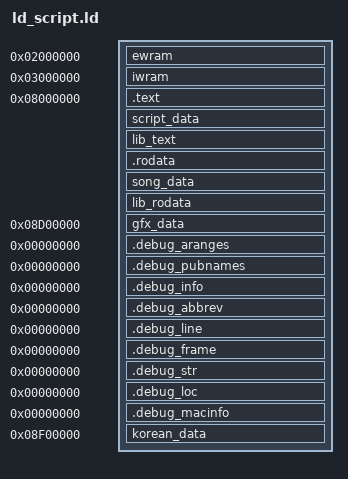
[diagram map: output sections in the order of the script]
ENTRY(Start)

gNumMusicPlayers = 4;
gMaxLines = 60;

SECTIONS {
    . = 0x2000000;

    ewram (NOLOAD) :
    ALIGN(4)
    {
. = ALIGN(4);
src/engine/main.o(ewram_data);
. = ALIGN(4);
src/engine/sprite.o(ewram_data);
. = ALIGN(4);
src/engine/text.o(ewram_data);
. = ALIGN(4);
src/engine/string_util.o(ewram_data);
. += 0x2E8;
. = ALIGN(4);
src/engine/link.o(ewram_data);
. = ALIGN(4);
src/rom3.o(ewram_data);
. = ALIGN(4);
gUnknown_020238C8 = .;
. += 0x4;
gDisplayedStringBattle = .;
. += 0x12C;
gBattleTypeFlags = .;
. += 0x4;
gUnknown_020239FC = .;
. += 0x4;
gUnknown_02023A00 = .;
. += 0x4;
gUnknown_02023A04 = .;
. += 0x10;
gUnknown_02023A14 = .;
. += 0x4C;
gBattleBufferA = .;
. += 0x2;
gUnknown_02023A62 = .;
. += 0x1;
gUnknown_02023A63 = .;
. += 0x1;
gUnknown_02023A64 = .;
. += 0x7FC;
gBattleBufferB = .;
. += 0x4;
gUnknown_02024264 = .;
. += 0x7FC;
gActiveBank = .;
. += 0x4;
gBattleExecBuffer = .;
. += 0x4;
gNoOfAllBanks = .;
. += 0x2;
gBattlePartyID = .;
. += 0x8;
gBanksBySide = .;
. += 0x4;
gUnknown_02024A76 = .;
. += 0x4;
gTurnOrder = .;
. += 0x4;
gCurrentMoveTurn = .;
. += 0x1;
gFightStateTracker = .;
. += 0x1;
gBattleMons = .;
. += 0xC;
gUnknown_02024A8C = .;
. += 0xC;
gUnknown_02024A98 = .;
. += 0xC;
gUnknown_02024AA4 = .;
. += 0x4;
gUnknown_02024AA8 = .;
. += 0x24;
gUnknown_02024ACC = .;
. += 0x4;
gUnknown_02024AD0 = .;
. += 0x110;
gObjectBankIDs = .;
. += 0x4;
gCurrMovePos = .;
. += 0x1;
gUnknown_02024BE5 = .;
. += 0x1;
gCurrentMove = .;
. += 0x2;
gUnknown_02024BE8 = .;
. += 0x2;
gRandomMove = .;
. += 0x2;
gBattleMoveDamage = .;
. += 0x4;
gHP_dealt = .;
. += 0x4;
gTakenDmg = .;
. += 0x10;
gLastUsedItem = .;
. += 0x2;
gLastUsedAbility = .;
. += 0x1;
gBankAttacker = .;
. += 0x1;
gBankTarget = .;
. += 0x1;
gBank1 = .;
. += 0x1;
gEffectBank = .;
. += 0x1;
gStringBank = .;
. += 0x1;
gAbsentBankFlags = .;
. += 0x1;
gCritMultiplier = .;
. += 0x1;
gMultiHitCounter = .;
. += 0x2;
gBattlescriptCurrInstr = .;
. += 0x8;
gActionForBanks = .;
. += 0x4;
gUnknown_02024C1C = .;
. += 0x10;
gUnknown_02024C2C = .;
. += 0x8;
gLastUsedMove = .;
. += 0x8;
gMoveHitWith = .;
. += 0x8;
gUnknown_02024C44 = .;
. += 0x8;
gUnknown_02024C4C = .;
. += 0x8;
gLockedMove = .;
. += 0x8;
gUnknown_02024C5C = .;
. += 0x4;
gChosenMovesByBanks = .;
. += 0x8;
gBattleMoveFlags = .;
. += 0x4;
gHitMarker = .;
. += 0x4;
gUnknown_02024C70 = .;
. += 0x4;
gTakenDmgBanks = .;
. += 0x4;
gUnknown_02024C78 = .;
. += 0x2;
gSideAffecting = .;
. += 0x6;
gSideTimer = .;
. += 0x18;
gStatuses3 = .;
. += 0x10;
gDisableStructs = .;
. += 0x70;
gPauseCounterBattle = .;
. += 0x2;
gPaydayMoney = .;
. += 0x2;
gRandomTurnNumber = .;
. += 0x2;
gBattleCommunication = .;
. += 0x1;
gUnknown_02024D1F = .;
. += 0x7;
gBattleOutcome = .;
. += 0x2;
gProtectStructs = .;
. += 0x40;
gSpecialStatuses = .;
. += 0x50;
gBattleWeather = .;
. += 0x4;
gWishFutureKnock = .;
. += 0x20;
gUnknown_02024DDC = .;
. += 0xC;
gUnknown_02024DE8 = .;
. += 0x2;
gSentPokesToOpponent = .;
. += 0x2;
gDynamicBasePower = .;
. += 0x2;
gExpShareExp = .;
. += 0x2;
gEnigmaBerries = .;
. += 0x8;
gUnknown_02024DF8 = .;
. += 0x68;
gActionSelectionCursor = .;
. += 0x4;
gMoveSelectionCursor = .;
. += 0x4;
gUnknown_02024E68 = .;
. += 0x4;
gBankInMenu = .;
. += 0x1;
gDoingBattleAnim = .;
. += 0x3;
gPID_perBank = .;
. += 0x10;
gBattleMovePower = .;
. += 0x2;
gMoveToLearn = .;
. += 0x2;
gBattleMonForms = .;
. += 0x4;
. = ALIGN(4);
src/pokemon/pokemon_1.o(ewram_data);
. = ALIGN(4);
src/pokemon/pokemon_2.o(ewram_data);
. = ALIGN(4);
src/engine/load_save.o(ewram_data);
gUnknown_020296CC = .;
. += 0x34;
gUnknown_02029700 = .;
. += 0xD8;
gUnknown_020297D8 = .;
. += 0x4;
. = ALIGN(4);
src/scene/berry_blender.o(ewram_data);
. = ALIGN(4);
src/scene/new_game.o(ewram_data);
. = ALIGN(4);
src/field/overworld.o(ewram_data);
. = ALIGN(4);
src/field/fieldmap.o(ewram_data);
. = ALIGN(4);
src/field/field_camera.o(ewram_data);
. = ALIGN(4);
src/field/field_player_avatar.o(ewram_data);
. = ALIGN(4);
src/field/field_message_box.o(ewram_data);
. = ALIGN(4);
src/engine/script.o(ewram_data);
. = ALIGN(4);
src/field/scrcmd.o(ewram_data);
. = ALIGN(4);
src/field/field_control_avatar.o(ewram_data);
. = ALIGN(4);
src/field/event_data.o(ewram_data);
. = ALIGN(4);
gUnknown_0202E8F4 = .;
. += 0x1;
gUnknown_0202E8F5 = .;
. += 0x1;
gUnknown_0202E8F6 = .;
. += 0x2;
gUnknown_0202E8F8 = .;
. += 0x2;
gPartyMenuType = .;
. += 0x2;
. = ALIGN(4);
src/field/start_menu.o(ewram_data);
. = ALIGN(4);
src/engine/menu.o(ewram_data);
. = ALIGN(4);
src/engine/tileset_anim.o(ewram_data);
. = ALIGN(4);
src/engine/palette.o(ewram_data);
. = ALIGN(4);
src/engine/sound.o(ewram_data);
. = ALIGN(4);
src/battle/battle_anim.o(ewram_data);
. = ALIGN(4);
src/rom_8077ABC.o(ewram_data);
. = ALIGN(4);
src/scene/title_screen.o(ewram_data);
. = ALIGN(4);
gUnknown_0202F7E8 = .;
. += 0x200;
gUnknown_0202F9E8 = .;
. += 0x260;
gUnknown_0202FC48 = .;
. += 0x2F0;
gUnknown_0202FF38 = .;
. += 0x20;
gUnknown_0202FF58 = .;
. += 0x4;
. = ALIGN(4);
src/battle/battle_setup.o(ewram_data);
. = ALIGN(4);
src/field/wild_encounter.o(ewram_data);
. = ALIGN(4);
src/field/field_effect.o(ewram_data);
gUnknown_0202FFA4 = .;
. += 0x4;
. = ALIGN(4);
src/pokemon/pokemon_menu.o(ewram_data);
. = ALIGN(4);
src/pokemon/pokedex.o(ewram_data);
. = ALIGN(4);
src/engine/trainer_card.o(ewram_data);
. = ALIGN(4);
src/pokemon/pokemon_storage_system.o(ewram_data);
. = ALIGN(4);
gUnknown_02038470 = .;
. += 0x3;
gUnknown_02038473 = .;
. += 0x1;
gUnknown_02038474 = .;
. += 0x4;
gUnknown_02038478 = .;
. += 0x4;
gUnknown_0203847C = .;
. += 0x1;
gUnknown_0203847D = .;
. += 0x1;
gUnknown_0203847E = .;
. += 0x1;
gUnknown_0203847F = .;
. += 0x1;
gUnknown_02038480 = .;
. += 0x64;
gUnknown_020384E4 = .;
. += 0x1;
gUnknown_020384E5 = .;
. += 0x1;
gUnknown_020384E6 = .;
. += 0x1;
gUnknown_020384E7 = .;
. += 0x1;
gUnknown_020384E8 = .;
. += 0x1;
gUnknown_020384E9 = .;
. += 0x1;
gUnknown_020384EA = .;
. += 0x2;
gUnknown_020384EC = .;
. += 0x4;
gUnknown_020384F0 = .;
. += 0x4;
gUnknown_020384F4 = .;
. += 0x4;
. = ALIGN(4);
src/field/script_movement.o(ewram_data);
. = ALIGN(4);
src/field/map_name_popup.o(ewram_data);
. = ALIGN(4);
src/field/item_menu.o(ewram_data);
. = ALIGN(4);
gUnknown_0203856C = .;
. += 0x4;
gContestMons = .;
. += 0xD;
gUnknown_0203857D = .;
. += 0x11;
gUnknown_0203858E = .;
. += 0x8;
gUnknown_02038596 = .;
. += 0xDA;
gUnknown_02038670 = .;
. += 0x8;
gUnknown_02038678 = .;
. += 0x8;
gUnknown_02038680 = .;
. += 0x8;
gUnknown_02038688 = .;
. += 0x8;
gUnknown_02038690 = .;
. += 0x4;
gUnknown_02038694 = .;
. += 0x1;
gContestPlayerMonIndex = .;
. += 0x1;
gUnknown_02038696 = .;
. += 0x4;
gIsLinkContest = .;
. += 0x1;
gUnknown_0203869B = .;
. += 0x1;
gScriptContestCategory = .;
. += 0x2;
gScriptContestRank = .;
. += 0x2;
. = ALIGN(4);
src/field/shop.o(ewram_data);
. = ALIGN(4);
src/field/money.o(ewram_data);
. = ALIGN(4);
gUnknown_02038738 = .;
. += 0x78;
. = ALIGN(4);
src/debug/sound_check_menu.o(ewram_data);
. = ALIGN(4);
gUnknown_020387DC = .;
. += 0x4;
. = ALIGN(4);
src/field/tv.o(ewram_data);
. = ALIGN(4);
gUnknown_020387EC = .;
. += 0x4;
. = ALIGN(4);
src/field/rotating_gate.o(ewram_data);
. = ALIGN(4);
src/field/safari_zone.o(ewram_data);
gUnknown_020388AC = .;
. += 0x4;
gUnknown_020388B0 = .;
. += 0x4;
gUnknown_020388B4 = .;
. += 0x4;
. = ALIGN(4);
src/pokemon/mon_markings.o(ewram_data);
. = ALIGN(4);
src/field/mauville_man.o(ewram_data);
. = ALIGN(4);
src/field/menu_helpers.o(ewram_data);
. = ALIGN(4);
src/field/region_map.o(ewram_data);
. = ALIGN(4);
src/field/decoration.o(ewram_data);
. = ALIGN(4);
src/battle/battle_ai.o(ewram_data);
. = ALIGN(4);
src/rom6.o(ewram_data);
. = ALIGN(4);
src/field/pokeblock.o(ewram_data);
. = ALIGN(4);
src/field/field_specials.o(ewram_data);
. = ALIGN(4);
gUnknown_02039260 = .;
. += 0x2;
gUnknown_02039262 = .;
. += 0x2;
gUnknown_02039264 = .;
. += 0x2;
gUnknown_02039266 = .;
. += 0x2;
gUnknown_02039268 = .;
. += 0x2;
gUnknown_0203926A = .;
. += 0x2;
gAbilitiesPerBank = .;
. += 0x4;
. = ALIGN(4);
src/field/choose_party.o(ewram_data);
. = ALIGN(4);
gUnknown_02039274 = .;
. += 0x4;
gUnknown_02039278 = .;
. += 0x1;
gUnknown_02039279 = .;
. += 0x1;
gUnknown_0203927A = .;
. += 0x1;
gUnknown_0203927B = .;
. += 0x1;
gUnknown_0203927C = .;
. += 0x1;
gUnknown_0203927D = .;
. += 0x7;
. = ALIGN(4);
src/engine/save.o(ewram_data);
. = ALIGN(4);
src/engine/mystery_event_script.o(ewram_data);
. = ALIGN(4);
src/field/roamer.o(ewram_data);
. = ALIGN(4);
src/field/use_pokeblock.o(ewram_data);
. = ALIGN(4);
src/field/player_pc.o(ewram_data);
. = ALIGN(4);
src/scene/intro.o(ewram_data);
. = ALIGN(4);
src/scene/hall_of_fame.o(ewram_data);
. = ALIGN(4);
src/scene/credits.o(ewram_data);
. = ALIGN(4);
src/field/lottery_corner.o(ewram_data);
. = ALIGN(4);
src/field/berry_tag_screen.o(ewram_data);
. = ALIGN(4);
src/engine/mystery_event_menu.o(ewram_data);
. = ALIGN(4);
src/engine/save_failed_screen.o(ewram_data);
. = ALIGN(4);
src/pokemon/pokeblock_feed.o(ewram_data);
gUnknown_02039358 = .;
. += 0x2;
gUnknown_0203935A = .;
. += 0x2;
gUnknown_0203935C = .;
. += 0x4;
gTileBuffer = .;
. += 0x100;
gUnknown_02039460 = .;
. += 0x300;
gUnknown_02039760 = .;
. += 0xC00;
gUnknown_0203A360 = .;
. += 0x20;
. = ALIGN(4);
src/engine/menu_cursor.o(ewram_data);

        . = 0x40000;
    }

    . = 0x3000000;

    iwram (NOLOAD) :
    ALIGN(4)
    {
        /* .bss starts at 0x3000000 */
. = ALIGN(4);
src/engine/main.o(.bss);
. = ALIGN(4);
src/engine/sprite.o(.bss);
. = ALIGN(4);
src/engine/text.o(.bss);
. = ALIGN(4);
src/engine/string_util.o(.bss);
. = ALIGN(4);
src/engine/link.o(.bss);
. = ALIGN(4);
src/engine/rtc.o(.bss);
. = ALIGN(4);
src/field/daycare.o(.bss);
. = ALIGN(4);
src/engine/trade.o(.bss);
. = ALIGN(4);
src/scene/berry_blender.o(.bss);
. = ALIGN(4);
src/engine/play_time.o(.bss);
. = ALIGN(4);
src/field/overworld.o(.bss);
. = ALIGN(4);
src/field/field_camera.o(.bss);
. = ALIGN(4);
src/field/field_map_obj.o(.bss);
. = ALIGN(4);
src/field/field_message_box.o(.bss);
. = ALIGN(4);
src/engine/text_window.o(.bss);
. = ALIGN(4);
src/engine/script.o(.bss);
. = ALIGN(4);
src/field/start_menu.o(.bss);
. = ALIGN(4);
src/engine/menu.o(.bss);
. = ALIGN(4);
src/engine/tileset_anim.o(.bss);
. = ALIGN(4);
src/engine/sound.o(.bss);
. = ALIGN(4);
src/field/field_weather.o(.bss);
. = ALIGN(4);
src/field/field_effect.o(.bss);
. = ALIGN(4);
src/field/item_menu.o(.bss);
. = ALIGN(4);
src/field/shop.o(.bss);
. = ALIGN(4);
src/engine/record_mixing.o(.bss);
. = ALIGN(4);
src/field/tv.o(.bss);
. = ALIGN(4);
src/battle/battle_anim_80CA710.o(.bss);
. = ALIGN(4);
src/field/easy_chat.o(.bss);
. = ALIGN(4);
src/pokenav_before.o(.bss);
. = ALIGN(4);
src/field/mauville_man.o(.bss);
. = ALIGN(4);
src/field/menu_helpers.o(.bss);
. = ALIGN(4);
src/scene/contest_painting.o(.bss);
. = ALIGN(4);
src/field/pokeblock.o(.bss);
. = ALIGN(4);
src/field/field_specials.o(.bss);
. = ALIGN(4);
src/pokemon/learn_move.o(.bss);
. = ALIGN(4);
src/field/player_pc.o(.bss);
. = ALIGN(4);
asm/m4a_1.o(.bss);
. = ALIGN(4);
src/libs/agb_flash.o(.bss);
. = ALIGN(4);
src/libs/siirtc.o(.bss);
. = ALIGN(4);
../../tools/agbcc/lib/libgcc.a:dp-bit.o(.bss);
. = ALIGN(4);
../../tools/agbcc/lib/libgcc.a:fp-bit.o(.bss);

        /* .bss.code starts at 0x3000F60 */
        src/libs/m4a_2.o(.bss.code);

        /* COMMON starts at 0x3001760 */
. = ALIGN(4);
. = ALIGN(4);
gKeyRepeatStartDelay = .;
. += 0x4;
. = ALIGN(4);
gLinkTransferringData = .;
. += 0x4;
. = ALIGN(16);
gMain = .;
. += 0x440;
. = ALIGN(4);
gKeyRepeatContinueDelay = .;
. += 0x4;
. = ALIGN(4);
gSoftResetDisabled = .;
. += 0x4;
. = ALIGN(16);
gIntrTable = .;
. += 0x38;
. = ALIGN(4);
gLinkVSyncDisabled = .;
. += 0x4;
. = ALIGN(16);
IntrMain_Buffer = .;
. += 0x800;
. = ALIGN(4);
gPcmDmaCounter = .;
. += 0x4;
. = ALIGN(4);
. = ALIGN(16);
gSpriteOrder = .;
. += 0x40;
. = ALIGN(16);
gSpriteTileAllocBitmap = .;
. += 0x80;
. = ALIGN(4);
gSpriteCoordOffsetX = .;
. += 0x4;
. = ALIGN(4);
gOamLimit = .;
. += 0x4;
. = ALIGN(4);
gReservedSpriteTileCount = .;
. += 0x4;
. = ALIGN(4);
gSpriteCopyRequestCount = .;
. += 0x4;
. = ALIGN(16);
gSpriteCopyRequests = .;
. += 0x300;
. = ALIGN(4);
gSpriteCoordOffsetY = .;
. += 0x4;
. = ALIGN(16);
gOamMatrices = .;
. += 0x100;
. = ALIGN(4);
gShouldProcessSpriteCopyRequests = .;
. += 0x4;
. = ALIGN(4);
gOamMatrixAllocBitmap = .;
. += 0x4;
. = ALIGN(4);
gReservedSpritePaletteCount = .;
. += 0x4;
. = ALIGN(4);
. = ALIGN(16);
gUnknownStringVar = .;
. += 0x10;
. = ALIGN(4);
. = ALIGN(8);
word_3002910 = .;
. += 0x8;
. = ALIGN(4);
gLinkDebugValue1 = .;
. += 0x4;
. = ALIGN(16);
localLinkPlayerBlock = .;
. += 0x3C;
. = ALIGN(4);
gLinkErrorOccurred = .;
. += 0x4;
. += 0x4;
. = ALIGN(4);
gLinkDebugValue2 = .;
. += 0x4;
. += 0x4;
. = ALIGN(4);
gLinkPlayerPending = .;
. += 0x4;
. = ALIGN(16);
gLinkPlayers = .;
. += 0x70;
. = ALIGN(4);
gBlockReceived = .;
. += 0x4;
. += 0x4;
. = ALIGN(4);
gLinkHeldKeys = .;
. += 0x4;
. = ALIGN(4);
gLinkTimeOutCounter = .;
. += 0x4;
. += 0x4;
. = ALIGN(16);
localLinkPlayer = .;
. += 0x1C;
. = ALIGN(16);
gRecvCmds = .;
. += 0x40;
. = ALIGN(4);
gLinkStatus = .;
. += 0x4;
. = ALIGN(4);
gLinkDummyBool = .;
. += 0x4;
. = ALIGN(4);
byte_3002A68 = .;
. += 0x4;
. = ALIGN(16);
gBlockSendBuffer = .;
. += 0x100;
. = ALIGN(4);
u8_array_3002B70 = .;
. += 0x4;
. = ALIGN(4);
gLinkType = .;
. += 0x4;
. = ALIGN(4);
u8_array_3002B78 = .;
. += 0x4;
. = ALIGN(16);
gBlockRecvBuffer = .;
. += 0x400;
. = ALIGN(4);
gSuppressLinkErrorMessage = .;
. += 0x4;
. = ALIGN(4);
gSavedLinkPlayerCount = .;
. += 0x4;
. = ALIGN(16);
gSendCmd = .;
. += 0x10;
. = ALIGN(4);
gSavedMultiplayerId = .;
. += 0x4;
. = ALIGN(4);
gReceivedRemoteLinkPlayers = .;
. += 0x4;
. = ALIGN(16);
gLinkTestBGInfo = .;
. += 0x10;
. = ALIGN(4);
gLinkCallback = .;
. += 0x4;
. = ALIGN(16);
gSavedLinkPlayers = .;
. += 0x70;
. = ALIGN(4);
gShouldAdvanceLinkState = .;
. += 0x4;
. = ALIGN(8);
gLinkTestBlockChecksums = .;
. += 0x8;
. += 0x4;
. = ALIGN(4);
gBlockRequestType = .;
. += 0x4;
. += 0x4;
. += 0x4;
. = ALIGN(4);
gLastSendQueueCount = .;
. += 0x4;
. = ALIGN(16);
gLink = .;
. += 0xFC0;
. = ALIGN(4);
gLastRecvQueueCount = .;
. += 0x4;
. = ALIGN(4);
gLinkSavedIme = .;
. += 0x4;
. = ALIGN(4);
. = ALIGN(8);
gLocalTime = .;
. += 0x8;
. = ALIGN(4);
. = ALIGN(16);
gBattleBuffersTransferData = .;
. += 0x170;
. = ALIGN(4);
gUnknown_030041B0 = .;
. += 0x4;
gUnknown_030041B4 = .;
. += 0x4;
gUnknown_030041B8 = .;
. += 0x8;
gBattleTextBuff1 = .;
. += 0x10;
gUnknown_030041D0 = .;
. += 0x30;
gUnknown_03004200 = .;
. += 0x10;
gUnknown_03004210 = .;
. += 0x30;
gUnknown_03004240 = .;
. += 0x4;
gUnknown_03004244 = .;
. += 0xC;
gUnknown_03004250 = .;
. += 0x30;
gUnknown_03004280 = .;
. += 0x4;
gUnknown_03004284 = .;
. += 0x4;
gUnknown_03004288 = .;
. += 0x4;
gBattleTerrain = .;
. += 0x4;
gBattleTextBuff2 = .;
. += 0x10;
gUnknown_030042A0 = .;
. += 0x4;
gUnknown_030042A4 = .;
. += 0xC;
gBattleTextBuff3 = .;
. += 0x10;
gUnknown_030042C0 = .;
. += 0x4;
gUnknown_030042C4 = .;
. += 0xC;
gPreBattleCallback1 = .;
. += 0x4;
gBattleMainFunc = .;
. += 0xC;
gBattleResults = .;
. += 0x1C;
gUnknown_030042FC = .;
. += 0xE;
gUnknown_0300430A = .;
. += 0xC;
gUnknown_03004316 = .;
. += 0xE;
gLeveledUpInBattle = .;
. += 0xC;
gBattleBankFunc = .;
. += 0x10;
gHealthboxIDs = .;
. += 0x4;
gUnknown_03004344 = .;
. += 0x4;
gUnknown_03004348 = .;
. += 0x4;
gUnknown_0300434C = .;
. += 0x4;
. = ALIGN(4);
. = ALIGN(4);
gPlayerPartyCount = .;
. += 0x4;
. = ALIGN(16);
gPlayerParty = .;
. += 0x258;
. = ALIGN(4);
gEnemyPartyCount = .;
. += 0x4;
. = ALIGN(16);
gEnemyParty = .;
. += 0x258;
. = ALIGN(4);
. = ALIGN(4);
gRngValue = .;
. += 0x4;
. = ALIGN(4);
. = ALIGN(4);
gEggHatchData = .;
. += 0x4;
. = ALIGN(4);
. = ALIGN(4);
gFlashMemoryPresent = .;
. += 0x4;
gUnknown_03004824 = .;
. += 0x4;
gUnknown_03004828 = .;
. += 0x8;
. = ALIGN(4);
. = ALIGN(4);
gUnknown_03004830 = .;
. += 0x4;
. = ALIGN(4);
gInGameOpponentsNo = .;
. += 0x4;
. = ALIGN(16);
gUnknown_03004840 = .;
. += 0x14;
. = ALIGN(4);
gBerryBlenderData = .;
. += 0x4;
. = ALIGN(4);
. = ALIGN(4);
word_3004858 = .;
. += 0x4;
. = ALIGN(4);
gFieldCallback = .;
. += 0x4;
. = ALIGN(4);
gUnknown_03004860 = .;
. += 0x4;
. = ALIGN(4);
gFieldLinkPlayerCount = .;
. += 0x4;
. = ALIGN(4);
. = ALIGN(16);
gUnknown_03004870 = .;
. += 0xC;
. = ALIGN(4);
. = ALIGN(16);
gUnknown_03004880 = .;
. += 0x18;
. = ALIGN(4);
gUnknown_03004898 = .;
. += 0x4;
. = ALIGN(4);
gUnknown_0300489C = .;
. += 0x4;
. = ALIGN(4);
. = ALIGN(16);
gMapObjects = .;
. += 0x240;
. = ALIGN(4);
. = ALIGN(4);
gSelectedMapObject = .;
. += 0x4;
. = ALIGN(4);
gUnknown_03004AE4 = .;
. += 0x4;
. = ALIGN(4);
. = ALIGN(4);
gCallback_03004AE8 = .;
. += 0x4;
. = ALIGN(4);
. = ALIGN(4);
gDisableMusic = .;
. += 0x4;
. = ALIGN(4);
. = ALIGN(4);
gSoundAnimFramesToWait = .;
. += 0x4;
. = ALIGN(16);
gBattleAnimArgs = .;
. += 0x10;
. = ALIGN(16);
gAnimSpriteIndexArray = .;
. += 0x10;
. = ALIGN(4);
. = ALIGN(16);
gTasks = .;
. += 0x280;
. = ALIGN(4);
. = ALIGN(16);
gUnknown_03004DA0 = .;
. += 0x20;
. = ALIGN(16);
gUnknown_03004DC0 = .;
. += 0x20;
gUnknown_03004DE0 = .;
. += 0x2;
gUnknown_03004DE2 = .;
. += 0x2;
gUnknown_03004DE4 = .;
. += 0x27C;
gUnknown_03005060 = .;
. += 0x500;
gUnknown_03005560 = .;
. += 0x140;
gUnknown_030056A0 = .;
. += 0x640;
. = ALIGN(4);
. = ALIGN(4);
gLastFieldPokeMenuOpened = .;
. += 0x4;
. = ALIGN(4);
gUnknown_03005CE4 = .;
. += 0x4;
. = ALIGN(4);
. = ALIGN(4);
gUnknown_03005CE8 = .;
. += 0x4;
. = ALIGN(4);
gUnknown_03005CEC = .;
. += 0x4;
. = ALIGN(16);
gUnknown_03005CF0 = .;
. += 0x10;
. = ALIGN(16);
gFieldItemUseCallback = .;
. += 0x10;
gBagPocketScrollStates = .;
. += 0x14;
gCurrentBagPocketItemSlots = .;
. += 0x4;
. = ALIGN(4);
gUnknown_03005D28 = .;
. += 0x4;
. = ALIGN(4);
. = ALIGN(4);
gUnknown_03005D2C = .;
. += 0x4;
. = ALIGN(4);
. = ALIGN(4);
gUnknown_03005D30 = .;
. += 0x4;
. = ALIGN(4);
gSoundTestCryNum = .;
. += 0x4;
. = ALIGN(4);
. = ALIGN(4);
gUnknown_03005D38 = .;
. += 0x4;
. += 0x64;
. = ALIGN(16);
gUnknown_03005DA0 = .;
. += 0x48;
gUnknown_03005DE8 = .;
. += 0x4;
gUnknown_03005DEC = .;
. += 0x4;
gUnknown_03005DF0 = .;
. += 0x4;
gUnknown_03005DF4 = .;
. += 0x4;
gUnknown_03005DF8 = .;
. += 0x4;
gUnknown_03005DFC = .;
. += 0x4;
gUnknown_03005E00 = .;
. += 0x4;
gUnknown_03005E04 = .;
. += 0x4;
gUnknown_03005E08 = .;
. += 0x4;
gUnknown_03005E0C = .;
. += 0x4;
. = ALIGN(4);
. = ALIGN(4);
gUnknown_03005E10 = .;
. += 0x4;
. = ALIGN(16);
gUnknown_03005E20 = .;
. += 0x20;
. = ALIGN(16);
gUnknown_03005E40 = .;
. += 0x4C;
. = ALIGN(4);
gUnknown_03005E8C = .;
. += 0x4;
. = ALIGN(4);
gUnknown_03005E90 = .;
. += 0x4;
. = ALIGN(4);
. = ALIGN(4);
gCB2_AfterEvolution = .;
. += 0x4;
gUnknown_03005E98 = .;
. += 0x4;
. = ALIGN(4);
. = ALIGN(4);
gLastWrittenSector = .;
. += 0x4;
. = ALIGN(4);
gLastSaveCounter = .;
. += 0x4;
. = ALIGN(4);
gLastKnownGoodSector = .;
. += 0x4;
. = ALIGN(4);
gDamagedSaveSectors = .;
. += 0x4;
. = ALIGN(4);
gSaveCounter = .;
. += 0x4;
. = ALIGN(4);
gFastSaveSection = .;
. += 0x4;
. = ALIGN(4);
gUnknown_03005EB4 = .;
. += 0x4;
. = ALIGN(4);
gSaveFileStatus = .;
. += 0x4;
. = ALIGN(4);
gGameContinueCallback = .;
. += 0x4;
. += 0x10;
. = ALIGN(4);
. = ALIGN(4);
gIntroFrameCounter = .;
. += 0x4;
. = ALIGN(16);
gMultibootProgramStruct = .;
. += 0x2C;
. = ALIGN(4);
gUnknown_03005F0C = .;
. += 0x4;
gUnknown_03005F10 = .;
. += 0x4;
gUnknown_03005F14 = .;
. += 0xC;
. = ALIGN(4);
. = ALIGN(4);
gPokeblockFeedPokeSprite = .;
. += 0x4;
. = ALIGN(4);
gPokeblockFeedMonSpecies = .;
. += 0x4;
. = ALIGN(4);
gPokeblockMonNotFlipped = .;
. += 0x4;
. = ALIGN(4);
gPokeblockFeedMonSpriteID = .;
. += 0x4;
. = ALIGN(4);
gPokeblockFeedMonNature = .;
. += 0x4;
. = ALIGN(4);
gUnknown_03005F34 = .;
. += 0x4;
. = ALIGN(4);
gPokeblockFeedUnused0 = .;
. += 0x4;
. = ALIGN(4);
gUnknown_03005F3C = .;
. += 0x4;
. = ALIGN(4);
gUnknown_03005F40 = .;
. += 0x4;
. = ALIGN(16);
gPokeblockFeedPokeSpriteCopy = .;
. += 0x44;
. = ALIGN(4);
gUnknown_03005F94 = .;
. += 0x4;
. = ALIGN(16);
gUnknown_03005FA0 = .;
. += 0x30;
. = ALIGN(4);
. = ALIGN(16);
gSoundInfo = .;
. += 0xFB0;
. = ALIGN(16);
gPokemonCrySongs = .;
. += 0x68;
. = ALIGN(16);
gPokemonCryMusicPlayers = .;
. += 0x80;
. = ALIGN(16);
gMPlayJumpTable = .;
. += 0x90;
. = ALIGN(16);
gCgbChans = .;
. += 0x100;
. = ALIGN(16);
gPokemonCryTracks = .;
. += 0x140;
. = ALIGN(16);
gPokemonCrySong = .;
. += 0x34;
. = ALIGN(16);
gMPlay_BGM = .;
. += 0x40;
. = ALIGN(16);
gMPlay_SE1 = .;
. += 0x40;
. = ALIGN(16);
gMPlay_SE2 = .;
. += 0x40;
. = ALIGN(16);
gMPlayMemAccArea = .;
. += 0x10;
. = ALIGN(16);
gMPlay_SE3 = .;
. += 0x40;
. = ALIGN(4);
. = ALIGN(4);
gFlashTimeoutFlag = .;
. += 0x4;
. = ALIGN(4);
PollFlashStatus = .;
. += 0x4;
. = ALIGN(4);
WaitForFlashWrite = .;
. += 0x4;
. = ALIGN(4);
ProgramFlashSector = .;
. += 0x4;
. = ALIGN(4);
gFlash = .;
. += 0x4;
. = ALIGN(4);
ProgramFlashByte = .;
. += 0x4;
. = ALIGN(4);
gFlashNumRemainingBytes = .;
. += 0x4;
. = ALIGN(4);
EraseFlashChip = .;
. += 0x4;
. = ALIGN(4);
EraseFlashSector = .;
. += 0x4;
. = ALIGN(4);
gFlashMaxTime = .;
. += 0x4;

        . = 0x8000;
    }

    . = 0x8000000;

    .text :
    ALIGN(4)
    {
        asm/crt0.o(.text);
        src/engine/main.o(.text);
        src/engine/sprite.o(.text);
        src/engine/text.o(.text);
        src/engine/string_util.o(.text);
        src/engine/link.o(.text);
        src/engine/rtc.o(.text);
        src/engine/main_menu.o(.text);
        src/rom3.o(.text);
        src/engine/decompress.o(.text);
        asm/battle_1.o(.text);
        src/rom_800D42C.o(.text);
        asm/battle_1.o(.text_800DC24);
        src/battle/battle_2.o(.text);
        asm/battle_2.o(.text);
        src/battle/battle_3.o(.text);
        src/battle/battle_4.o(.text);
        src/battle/battle_controller_player.o(.text);
        src/battle/battle_7.o(.text);
        src/battle/battle_controller_opponent.o(.text);
        asm/battle_9.o(.text);
        src/battle/battle_controller_linkopponent.o(.text);
        src/pokemon/pokemon_1.o(.text);
        src/battle/calculate_base_damage.o(.text);
        src/pokemon/pokemon_2.o(.text);
        asm/pokemon_item_effect.o(.text);
        src/pokemon/pokemon_3.o(.text);
        src/engine/trig.o(.text);
        src/engine/rng.o(.text);
        src/engine/util.o(.text);
        src/engine/blend_palette.o(.text);
        src/field/daycare.o(.text);
        src/scene/egg_hatch.o(.text);
        src/battle/battle_interface.o(.text);
        src/battle/smokescreen.o(.text);
        src/battle/pokeball.o(.text);
        src/engine/load_save.o(.text);
        src/engine/trade.o(.text);
        src/scene/berry_blender.o(.text);
        src/engine/play_time.o(.text);
        src/scene/new_game.o(.text);
        src/field/overworld.o(.text);
        src/field/fieldmap.o(.text);
        src/field/metatile_behavior.o(.text);
        src/field/field_camera.o(.text);
        src/field/field_door.o(.text);
        src/field/field_player_avatar.o(.text);
        src/field/field_map_obj.o(.text);
        src/field/field_ground_effect.o(.text);
        src/field/field_map_obj_helpers.o(.text);
        src/field/field_message_box.o(.text);
        src/field/map_obj_lock.o(.text);
        src/engine/text_window.o(.text);
        src/engine/script.o(.text);
        src/field/scrcmd.o(.text);
        src/field/field_control_avatar.o(.text);
        src/field/event_data.o(.text);
        src/field/coord_event_weather.o(.text);
        src/field/field_tasks.o(.text);
        src/engine/clock.o(.text);
        src/engine/reset_rtc_screen.o(.text);
        src/field/party_menu.o(.text);
        src/field/start_menu.o(.text);
        src/engine/menu.o(.text);
        src/engine/tileset_anim.o(.text);
        src/engine/palette.o(.text);
        src/engine/sound.o(.text);
        src/battle/battle_anim.o(.text);
        src/rom_8077ABC.o(.text);
        src/engine/task.o(.text);
        src/battle/reshow_battle_screen.o(.text);
        src/battle/battle_anim_807B69C.o(.text);
        src/scene/title_screen.o(.text);
        src/field/field_weather.o(.text);
        asm/field_weather.o(.text);
        src/field/field_fadetransition.o(.text);
        src/field/field_screen_effect.o(.text);
        src/battle/battle_setup.o(.text);
        src/engine/cable_club.o(.text);
        src/debug/mori_debug_menu.o(.text);
        src/field/trainer_see.o(.text);
        src/field/wild_encounter.o(.text);
        src/field/field_effect.o(.text);
        src/unknown_task.o(.text);
        src/pokemon/pokemon_menu.o(.text);
        src/engine/option_menu.o(.text);
        src/pokemon/pokedex.o(.text);
        src/engine/trainer_card.o(.text);
        src/engine/save_menu_util.o(.text);
        src/battle/battle_party_menu.o(.text);
        asm/unk_text_8095904.o(.text);
        asm/pokemon_storage_system.o(.text);
        src/pokemon/pokemon_storage_system.o(.text);
        asm/pokemon_storage_system.o(.text_8098A38);
        src/pokemon/pokemon_icon.o(.text);
        asm/pokemon_summary_screen.o(.text);
        src/pokemon/pokemon_summary_screen.o(.text);
        asm/pokemon_summary_screen.o(.text_80A0958);
        src/field/script_movement.o(.text);
        src/field/fldeff_cut.o(.text);
        src/pokemon/mail_data.o(.text);
        src/field/map_name_popup.o(.text);
        src/field/item_menu.o(.text);
        src/battle/battle_anim_80A7E7C.o(.text);
        src/field/item.o(.text);
        src/debug/matsuda_debug_menu.o(.text);
        asm/contest.o(.text);
        src/field/shop.o(.text);
        src/field/berry.o(.text);
        src/field/script_menu.o(.text);
        src/engine/naming_screen.o(.text);
        src/field/money.o(.text);
        asm/contest_effect.o(.text);
        src/engine/record_mixing.o(.text);
        src/debug/sound_check_menu.o(.text);
        src/field/secret_base.o(.text);
        src/field/tv.o(.text);
        asm/contest_link_80C2020.o(.text);
        src/script_pokemon_util_80C4BF0.o(.text);
        src/field/field_poison.o(.text);
        src/pokemon/pokemon_size_record.o(.text);
        src/field/pc_screen_effect.o(.text);
        asm/pc_screen_effect.o(.text);
        src/field/fldeff_secretpower.o(.text);
        src/field/fldeff_secret_base_pc.o(.text);
        src/field/fldeff_decoration.o(.text);
        src/field/fldeff_poison.o(.text);
        src/field/fldeff_berrytree.o(.text);
        src/field/fldeff_recordmixing.o(.text);
        src/field/field_special_scene.o(.text);
        src/field/rotating_gate.o(.text);
        src/field/safari_zone.o(.text);
        asm/contest_link_80C857C.o(.text);
        src/field/item_use.o(.text);
		src/battle_anim_80CA710.o(.text);
        asm/battle_anim_80CA710.o(.text);
        src/field/bike.o(.text);
        asm/easy_chat.o(.text);
        src/field/easy_chat.o(.text);
        src/pokenav_before.o(.text);
        asm/pokenav.o(.text);
        src/pokenav_after.o(.text);
        asm/pokenav.o(.text_80F708C);
        src/pokemon/mon_markings.o(.text);
        src/field/mauville_man.o(.text);
        src/pokemon/mail.o(.text);
        src/field/menu_helpers.o(.text);
        src/script_pokemon_util_80F99CC.o(.text);
        src/field/dewford_trend.o(.text);
        src/field/heal_location.o(.text);
        src/field/region_map.o(.text);
        src/scene/cute_sketch.o(.text);
        asm/cute_sketch.o(.text);
        src/field/decoration.o(.text);
        asm/slot_machine.o(.text);
        src/field/slot_machine.o(.text);
        asm/slot_machine.o(.text_8104D30)
        src/field/slot_machine.o(.text_b);
        src/scene/contest_painting.o(.text);
        src/battle/battle_ai.o(.text);
        src/field/trader.o(.text);
        src/field/starter_choose.o(.text);
        src/field/wallclock.o(.text);
        src/rom6.o(.text);
        src/field/pokeblock.o(.text);
        src/field/fldeff_flash.o(.text);
        src/battle/post_battle_event_funcs.o(.text);
        src/engine/time_events.o(.text);
        src/field/birch_pc.o(.text);
        src/field/hof_pc.o(.text);
        src/field/field_specials.o(.text);
        src/battle/battle_records.o(.text);
        asm/pokedex_area_screen.o(.text);
        src/scene/evolution_scene.o(.text);
        asm/roulette.o(.text);
        asm/pokedex_cry_screen.o(.text);
        src/pokemon/pokedex_cry_screen.o(.text);
        asm/pokedex_cry_screen.o(.text_811A4F8);
        src/field/coins.o(.text);
        src/field/landmark.o(.text);
        src/field/fldeff_strength.o(.text);
        src/battle/battle_transition.o(.text);
        src/battle/battle_controller_linkpartner.o(.text);
        src/battle/battle_message.o(.text);
        src/field/choose_party.o(.text);
        asm/cable_car.o(.text);
        asm/roulette_util.o(.text);
        asm/cable_car_util.o(.text);
        src/unused_8124F94.o(.text);
        src/engine/save.o(.text);
        src/engine/mystery_event_script.o(.text);
        src/field/field_effect_helpers.o(.text);
        asm/contest_ai.o(.text);
        asm/battle_anim_81258BC.o(.text);
        src/battle/battle_controller_safari.o(.text);
        src/field/fldeff_sweetscent.o(.text);
        asm/battle_anim_812C144.o(.text);
        src/pokemon/learn_move.o(.text);
        src/field/fldeff_softboiled.o(.text);
        src/field/decoration_inventory.o(.text);
        src/field/roamer.o(.text);
        src/field/battle_tower.o(.text);
        src/field/use_pokeblock.o(.text);
        src/battle/battle_controller_wally.o(.text);
        src/field/player_pc.o(.text);
        src/scene/intro.o(.text);
        src/field/field_region_map.o(.text);
        asm/battle_anim_813F0F4.o(.text);
        src/scene/hall_of_fame.o(.text);
        src/scene/credits.o(.text);
        src/field/lottery_corner.o(.text);
        src/field/diploma.o(.text);
        src/field/berry_tag_screen.o(.text);
        src/engine/mystery_event_menu.o(.text);
        src/engine/save_failed_screen.o(.text);
        src/field/braille_puzzles.o(.text);
        src/pokemon/pokeblock_feed.o(.text);
        src/engine/clear_save_data_menu.o(.text);
        src/scene/intro_credits_graphics.o(.text);
        src/scene/evolution_graphics.o(.text);
        src/field/bard_music.o(.text);
        src/field/fldeff_teleport.o(.text);
        src/debug/unknown_debug_menu.o(.text);
        src/engine/name_string_util.o(.text);
        src/engine/menu_cursor.o(.text);
        src/engine/korean.o(.text);
    } =0

    script_data :
    ALIGN(4)
    {
        data/event_scripts.o(script_data);
        data/battle_anim_scripts.o(script_data);
        . = ALIGN(4);
        data/battle_scripts_1.o(script_data);
        data/field_effect_scripts.o(script_data);
        data/battle_scripts_2.o(script_data);
        data/battle_ai_scripts.o(script_data);
        data/contest_ai_scripts.o(script_data);
        data/mystery_event_script_cmd_table.o(script_data);
    } =0

    lib_text :
    ALIGN(4)
    {
        asm/libgcnmultiboot.o(.text);
        asm/m4a_1.o(.text);
        src/libs/m4a_2.o(.text);
        asm/m4a_3.o(.text);
        src/libs/m4a_4.o(.text);
        src/libs/agb_flash.o(.text);
        src/libs/agb_flash_1m.o(.text);
        src/libs/agb_flash_mx.o(.text);
        src/libs/siirtc.o(.text);
        asm/libagbsyscall.o(.text);
        ../../tools/agbcc/lib/libgcc.a:_call_via_rX.o(.text);
        ../../tools/agbcc/lib/libgcc.a:_divsi3.o(.text);
        ../../tools/agbcc/lib/libgcc.a:_dvmd_tls.o(.text);
        ../../tools/agbcc/lib/libgcc.a:_fixunsdfsi.o(.text);
        ../../tools/agbcc/lib/libgcc.a:_fixunssfsi.o(.text);
        ../../tools/agbcc/lib/libgcc.a:_modsi3.o(.text);
        ../../tools/agbcc/lib/libgcc.a:_muldi3.o(.text);
        ../../tools/agbcc/lib/libgcc.a:_udivdi3.o(.text);
        ../../tools/agbcc/lib/libgcc.a:_udivsi3.o(.text);
        ../../tools/agbcc/lib/libgcc.a:_umodsi3.o(.text);
        ../../tools/agbcc/lib/libgcc.a:dp-bit.o(.text);
        ../../tools/agbcc/lib/libgcc.a:fp-bit.o(.text);
        ../../tools/agbcc/lib/libgcc.a:_lshrdi3.o(.text);
        ../../tools/agbcc/lib/libgcc.a:_negdi2.o(.text);
        src/libs/libc.o(.text);
    } =0

    .rodata :
    ALIGN(4)
    {
        src/engine/main.o(.rodata);
        src/engine/sprite.o(.rodata);
        . += 0x8; /* Why the gap? */
        src/engine/text.o(.rodata);
        src/engine/string_util.o(.rodata);
        src/engine/link.o(.rodata);
        src/engine/rtc.o(.rodata);
        src/engine/main_menu.o(.rodata);
        data/data2a.o(.rodata);
        src/battle/battle_4.o(.rodata);
        src/battle/battle_controller_player.o(.rodata);
        data/data2b.o(.rodata);
        src/battle/battle_controller_opponent.o(.rodata);
        src/battle/battle_controller_linkopponent.o(.rodata);
        data/battle_moves.o(.rodata);
        src/battle/battle_3.o(.rodata);
        src/pokemon/pokemon_data.o(.rodata);
        . = ALIGN(4);
        src/engine/trig.o(.rodata);
        src/engine/util.o(.rodata);
        src/field/daycare.o(.rodata);
        src/scene/egg_hatch.o(.rodata);
        data/battle_interface.o(.rodata);
        src/battle/pokeball.o(.rodata);
        src/engine/trade.o(.rodata);
        src/scene/berry_blender.o(.rodata);
        src/scene/new_game.o(.rodata);
        src/field/overworld.o(.rodata);
        data/tilesets.o(.rodata);
        data/maps.o(.rodata);
        src/field/fieldmap.o(.rodata);
        src/field/metatile_behavior.o(.rodata);
        src/field/field_door.o(.rodata);
        src/field/field_player_avatar.o(.rodata);
        src/field/field_map_obj.o(.rodata);
        src/field/field_ground_effect.o(.rodata);
        data/field_map_obj_helpers.o(.rodata);
        src/engine/text_window.o(.rodata);
        src/engine/script.o(.rodata);
        src/field/scrcmd.o(.rodata);
        src/field/coord_event_weather.o(.rodata);
        src/field/field_tasks.o(.rodata);
        src/engine/reset_rtc_screen.o(.rodata);
        src/field/party_menu.o(.rodata);
        src/field/start_menu.o(.rodata);
        src/engine/menu.o(.rodata);
        src/engine/tileset_anim.o(.rodata);
        src/engine/palette.o(.rodata);
        src/engine/sound.o(.rodata);
        data/battle_anim.o(.rodata);
        src/battle/battle_anim.o(.rodata);
        src/rom_8077ABC.o(.rodata);
        data/map_events.o(.rodata);
        data/data_8393054.o(.rodata);
        src/engine/task.o(.rodata);
        src/battle/battle_anim_807B69C.o(.rodata);
        src/scene/title_screen.o(.rodata);
        src/field/field_weather.o(.rodata);
        data/field_weather.o(.rodata);
        src/field/field_screen_effect.o(.rodata);
        src/battle/battle_setup.o(.rodata);
        src/engine/cable_club.o(.rodata);
        src/debug/mori_debug_menu.o(.rodata);
        src/field/trainer_see.o(.rodata);
        data/trainer_see.o(.rodata);
        src/field/wild_encounter.o(.rodata);
        data/wild_encounter.o(.rodata);
        src/field/field_effect.o(.rodata);
        src/pokemon/pokemon_menu.o(.rodata);
        src/engine/option_menu.o(.rodata);
        src/pokemon/pokedex.o(.rodata);
        src/engine/trainer_card.o(.rodata);
        src/battle/battle_party_menu.o(.rodata);
        data/pokemon_storage_system.o(.rodata);
        src/pokemon/pokemon_icon.o(.rodata);
        data/pokemon_summary_screen.o(.rodata);
        data/fldeff_cut.o(.rodata);
        src/field/item_menu.o(.rodata);
        data/battle_anim_80A7E7C.o(.rodata);
        src/field/item.o(.rodata);
        src/debug/matsuda_debug_menu.o(.rodata);
        data/contest.o(.rodata);
        src/field/shop.o(.rodata);
        src/field/berry.o(.rodata);
        src/field/script_menu.o(.rodata);
        src/engine/naming_screen.o(.rodata);
        data/naming_screen.o(.rodata);
        src/field/money.o(.rodata);
        data/contest_effect.o(.rodata);
        src/engine/record_mixing.o(.data);
        src/engine/record_mixing.o(.rodata);
        src/debug/sound_check_menu.o(.rodata);
        src/field/secret_base.o(.rodata);
        src/field/tv.o(.rodata);
        data/contest_link_80C2020.o(.rodata);
        src/pokemon/pokemon_size_record.o(.rodata);
        src/field/pc_screen_effect.o(.rodata);
        data/pc_screen_effect.o(.rodata);
        data/fldeff_secretpower.o(.rodata);
        data/fldeff_decoration.o(.rodata);
        src/field/fldeff_recordmixing.o(.rodata);
        src/field/field_special_scene.o(.rodata);
        src/field/rotating_gate.o(.rodata);
        src/field/item_use.o(.rodata);
        data/battle_anim_80CA710.o(.rodata);
        src/field/bike.o(.rodata);
        data/easy_chat.o(.rodata);
        data/pokenav.o(.rodata);
        data/mon_markings.o(.rodata);
        src/field/mauville_man.o(.rodata);
        data/mail.o(.rodata);
        src/field/menu_helpers.o(.rodata);
        src/field/heal_location.o(.rodata);
        src/field/region_map.o(.rodata);
        data/cute_sketch.o(.rodata);
        src/field/decoration.o(.rodata);
        data/slot_machine.o(.rodata);
        src/scene/contest_painting.o(.rodata);
        src/battle/battle_ai.o(.rodata);
        src/field/trader.o(.rodata);
        src/field/starter_choose.o(.rodata);
        src/field/wallclock.o(.rodata);
        src/field/pokeblock.o(.rodata);
        src/field/fldeff_flash.o(.rodata);
        src/engine/time_events.o(.rodata);
        src/field/field_specials.o(.rodata);
        data/pokedex_area_screen.o(.rodata);
        src/scene/evolution_scene.o(.rodata);
        data/roulette.o(.rodata);
        data/pokedex_cry_screen.o(.rodata);
        data/landmark.o(.rodata);
        src/battle/battle_transition.o(.rodata);
        src/battle/battle_controller_linkpartner.o(.rodata);
        src/battle/battle_message.o(.rodata);
        src/field/choose_party.o(.rodata);
        data/cable_car.o(.rodata);
        src/engine/save.o(.rodata);
        src/field/field_effect_helpers.o(.rodata);
        data/contest_ai.o(.rodata);
        src/battle/battle_controller_safari.o(.rodata);
        data/battle_anim_812C144.o(.rodata);
        src/pokemon/learn_move.o(.rodata);
        src/field/decoration_inventory.o(.rodata);
        src/field/roamer.o(.rodata);
        src/field/battle_tower.o(.rodata);
        src/field/use_pokeblock.o(.rodata);
        src/battle/battle_controller_wally.o(.rodata);
        src/field/player_pc.o(.rodata);
        src/scene/intro.o(.rodata);
        data/battle_anim_813F0F4.o(.rodata);
        src/scene/hall_of_fame.o(.rodata);
        src/scene/credits.o(.rodata);
        src/field/lottery_corner.o(.rodata);
        src/field/diploma.o(.rodata);
        src/strings.o(.rodata);
        src/field/berry_tag_screen.o(.rodata);
        src/engine/save_failed_screen.o(.rodata);
        src/pokemon/pokeblock_feed.o(.rodata);
        data/intro_credits_graphics.o(.rodata);
        src/scene/evolution_graphics.o(.rodata);
        data/bard_music.o(.rodata);
        data/unknown_debug_menu.o(.rodata);
        data/strings2.o(.rodata);
        data/menu_cursor.o(.rodata);
        data/mystery_event_msg.o(.rodata);
        src/libs/m4a_tables.o(.rodata);
        data/sound_data.o(.rodata);
        src/engine/save_menu_util.o(.rodata);
        src/engine/korean.o(.rodata);
    } =0

    song_data :
    ALIGN(4)
    {
        ../../sound/songs/se_stop.o(.rodata);
        ../../sound/songs/se_kaifuku.o(.rodata);
        ../../sound/songs/se_pc_logon.o(.rodata);
        ../../sound/songs/se_pc_off.o(.rodata);
        ../../sound/songs/se_pc_on.o(.rodata);
        ../../sound/songs/se_select.o(.rodata);
        ../../sound/songs/se_win_open.o(.rodata);
        ../../sound/songs/se_wall_hit.o(.rodata);
        ../../sound/songs/se_door.o(.rodata);
        ../../sound/songs/se_kaidan.o(.rodata);
        ../../sound/songs/se_dansa.o(.rodata);
        ../../sound/songs/se_jitensya.o(.rodata);
        ../../sound/songs/se_kouka_l.o(.rodata);
        ../../sound/songs/se_kouka_m.o(.rodata);
        ../../sound/songs/se_kouka_h.o(.rodata);
        ../../sound/songs/se_bowa2.o(.rodata);
        ../../sound/songs/se_poke_dead.o(.rodata);
        ../../sound/songs/se_nigeru.o(.rodata);
        ../../sound/songs/se_jido_doa.o(.rodata);
        ../../sound/songs/se_naminori.o(.rodata);
        ../../sound/songs/se_ban.o(.rodata);
        ../../sound/songs/se_pin.o(.rodata);
        ../../sound/songs/se_boo.o(.rodata);
        ../../sound/songs/se_bowa.o(.rodata);
        ../../sound/songs/se_jyuni.o(.rodata);
        ../../sound/songs/se_a.o(.rodata);
        ../../sound/songs/se_i.o(.rodata);
        ../../sound/songs/se_u.o(.rodata);
        ../../sound/songs/se_e.o(.rodata);
        ../../sound/songs/se_o.o(.rodata);
        ../../sound/songs/se_n.o(.rodata);
        ../../sound/songs/se_seikai.o(.rodata);
        ../../sound/songs/se_hazure.o(.rodata);
        ../../sound/songs/se_exp.o(.rodata);
        ../../sound/songs/se_jite_pyoko.o(.rodata);
        ../../sound/songs/se_mu_pachi.o(.rodata);
        ../../sound/songs/se_tk_kasya.o(.rodata);
        ../../sound/songs/se_fu_zaku.o(.rodata);
        ../../sound/songs/se_fu_zaku2.o(.rodata);
        ../../sound/songs/se_fu_zuzuzu.o(.rodata);
        ../../sound/songs/se_ru_gashin.o(.rodata);
        ../../sound/songs/se_ru_gasyan.o(.rodata);
        ../../sound/songs/se_ru_bari.o(.rodata);
        ../../sound/songs/se_ru_hyuu.o(.rodata);
        ../../sound/songs/se_ki_gasyan.o(.rodata);
        ../../sound/songs/se_tk_warpin.o(.rodata);
        ../../sound/songs/se_tk_warpout.o(.rodata);
        ../../sound/songs/se_tu_saa.o(.rodata);
        ../../sound/songs/se_hi_turun.o(.rodata);
        ../../sound/songs/se_track_move.o(.rodata);
        ../../sound/songs/se_track_stop.o(.rodata);
        ../../sound/songs/se_track_haik.o(.rodata);
        ../../sound/songs/se_track_door.o(.rodata);
        ../../sound/songs/se_moter.o(.rodata);
        ../../sound/songs/se_card.o(.rodata);
        ../../sound/songs/se_save.o(.rodata);
        ../../sound/songs/se_kon.o(.rodata);
        ../../sound/songs/se_kon2.o(.rodata);
        ../../sound/songs/se_kon3.o(.rodata);
        ../../sound/songs/se_kon4.o(.rodata);
        ../../sound/songs/se_suikomu.o(.rodata);
        ../../sound/songs/se_nageru.o(.rodata);
        ../../sound/songs/se_toy_c.o(.rodata);
        ../../sound/songs/se_toy_d.o(.rodata);
        ../../sound/songs/se_toy_e.o(.rodata);
        ../../sound/songs/se_toy_f.o(.rodata);
        ../../sound/songs/se_toy_g.o(.rodata);
        ../../sound/songs/se_toy_a.o(.rodata);
        ../../sound/songs/se_toy_b.o(.rodata);
        ../../sound/songs/se_toy_c1.o(.rodata);
        ../../sound/songs/se_mizu.o(.rodata);
        ../../sound/songs/se_hashi.o(.rodata);
        ../../sound/songs/se_daugi.o(.rodata);
        ../../sound/songs/se_pinpon.o(.rodata);
        ../../sound/songs/se_fuusen1.o(.rodata);
        ../../sound/songs/se_fuusen2.o(.rodata);
        ../../sound/songs/se_fuusen3.o(.rodata);
        ../../sound/songs/se_toy_kabe.o(.rodata);
        ../../sound/songs/se_toy_dango.o(.rodata);
        ../../sound/songs/se_doku.o(.rodata);
        ../../sound/songs/se_esuka.o(.rodata);
        ../../sound/songs/se_t_ame.o(.rodata);
        ../../sound/songs/se_t_ame_e.o(.rodata);
        ../../sound/songs/se_t_ooame.o(.rodata);
        ../../sound/songs/se_t_ooame_e.o(.rodata);
        ../../sound/songs/se_t_koame.o(.rodata);
        ../../sound/songs/se_t_koame_e.o(.rodata);
        ../../sound/songs/se_t_kami.o(.rodata);
        ../../sound/songs/se_t_kami2.o(.rodata);
        ../../sound/songs/se_elebeta.o(.rodata);
        ../../sound/songs/se_hinsi.o(.rodata);
        ../../sound/songs/se_expmax.o(.rodata);
        ../../sound/songs/se_tamakoro.o(.rodata);
        ../../sound/songs/se_tamakoro_e.o(.rodata);
        ../../sound/songs/se_basabasa.o(.rodata);
        ../../sound/songs/se_regi.o(.rodata);
        ../../sound/songs/se_c_gaji.o(.rodata);
        ../../sound/songs/se_c_maku_u.o(.rodata);
        ../../sound/songs/se_c_maku_d.o(.rodata);
        ../../sound/songs/se_c_pasi.o(.rodata);
        ../../sound/songs/se_c_syu.o(.rodata);
        ../../sound/songs/se_c_pikon.o(.rodata);
        ../../sound/songs/se_reapoke.o(.rodata);
        ../../sound/songs/se_op_basyu.o(.rodata);
        ../../sound/songs/se_bt_start.o(.rodata);
        ../../sound/songs/se_dendou.o(.rodata);
        ../../sound/songs/se_jihanki.o(.rodata);
        ../../sound/songs/se_tama.o(.rodata);
        ../../sound/songs/se_z_scroll.o(.rodata);
        ../../sound/songs/se_z_page.o(.rodata);
        ../../sound/songs/se_pn_on.o(.rodata);
        ../../sound/songs/se_pn_off.o(.rodata);
        ../../sound/songs/se_z_search.o(.rodata);
        ../../sound/songs/se_tamago.o(.rodata);
        ../../sound/songs/se_tb_start.o(.rodata);
        ../../sound/songs/se_tb_kon.o(.rodata);
        ../../sound/songs/se_tb_kara.o(.rodata);
        ../../sound/songs/se_bidoro.o(.rodata);
        ../../sound/songs/se_w085.o(.rodata);
        ../../sound/songs/se_w085b.o(.rodata);
        ../../sound/songs/se_w231.o(.rodata);
        ../../sound/songs/se_w171.o(.rodata);
        ../../sound/songs/se_w233.o(.rodata);
        ../../sound/songs/se_w233b.o(.rodata);
        ../../sound/songs/se_w145.o(.rodata);
        ../../sound/songs/se_w145b.o(.rodata);
        ../../sound/songs/se_w145c.o(.rodata);
        ../../sound/songs/se_w240.o(.rodata);
        ../../sound/songs/se_w015.o(.rodata);
        ../../sound/songs/se_w081.o(.rodata);
        ../../sound/songs/se_w081b.o(.rodata);
        ../../sound/songs/se_w088.o(.rodata);
        ../../sound/songs/se_w016.o(.rodata);
        ../../sound/songs/se_w016b.o(.rodata);
        ../../sound/songs/se_w003.o(.rodata);
        ../../sound/songs/se_w104.o(.rodata);
        ../../sound/songs/se_w013.o(.rodata);
        ../../sound/songs/se_w196.o(.rodata);
        ../../sound/songs/se_w086.o(.rodata);
        ../../sound/songs/se_w004.o(.rodata);
        ../../sound/songs/se_w025.o(.rodata);
        ../../sound/songs/se_w025b.o(.rodata);
        ../../sound/songs/se_w152.o(.rodata);
        ../../sound/songs/se_w026.o(.rodata);
        ../../sound/songs/se_w172.o(.rodata);
        ../../sound/songs/se_w172b.o(.rodata);
        ../../sound/songs/se_w053.o(.rodata);
        ../../sound/songs/se_w007.o(.rodata);
        ../../sound/songs/se_w092.o(.rodata);
        ../../sound/songs/se_w221.o(.rodata);
        ../../sound/songs/se_w221b.o(.rodata);
        ../../sound/songs/se_w052.o(.rodata);
        ../../sound/songs/se_w036.o(.rodata);
        ../../sound/songs/se_w059.o(.rodata);
        ../../sound/songs/se_w059b.o(.rodata);
        ../../sound/songs/se_w010.o(.rodata);
        ../../sound/songs/se_w011.o(.rodata);
        ../../sound/songs/se_w017.o(.rodata);
        ../../sound/songs/se_w019.o(.rodata);
        ../../sound/songs/se_w028.o(.rodata);
        ../../sound/songs/se_w013b.o(.rodata);
        ../../sound/songs/se_w044.o(.rodata);
        ../../sound/songs/se_w029.o(.rodata);
        ../../sound/songs/se_w057.o(.rodata);
        ../../sound/songs/se_w056.o(.rodata);
        ../../sound/songs/se_w250.o(.rodata);
        ../../sound/songs/se_w030.o(.rodata);
        ../../sound/songs/se_w039.o(.rodata);
        ../../sound/songs/se_w054.o(.rodata);
        ../../sound/songs/se_w077.o(.rodata);
        ../../sound/songs/se_w020.o(.rodata);
        ../../sound/songs/se_w082.o(.rodata);
        ../../sound/songs/se_w047.o(.rodata);
        ../../sound/songs/se_w195.o(.rodata);
        ../../sound/songs/se_w006.o(.rodata);
        ../../sound/songs/se_w091.o(.rodata);
        ../../sound/songs/se_w146.o(.rodata);
        ../../sound/songs/se_w120.o(.rodata);
        ../../sound/songs/se_w153.o(.rodata);
        ../../sound/songs/se_w071b.o(.rodata);
        ../../sound/songs/se_w071.o(.rodata);
        ../../sound/songs/se_w103.o(.rodata);
        ../../sound/songs/se_w062.o(.rodata);
        ../../sound/songs/se_w062b.o(.rodata);
        ../../sound/songs/se_w048.o(.rodata);
        ../../sound/songs/se_w187.o(.rodata);
        ../../sound/songs/se_w118.o(.rodata);
        ../../sound/songs/se_w155.o(.rodata);
        ../../sound/songs/se_w122.o(.rodata);
        ../../sound/songs/se_w060.o(.rodata);
        ../../sound/songs/se_w185.o(.rodata);
        ../../sound/songs/se_w014.o(.rodata);
        ../../sound/songs/se_w043.o(.rodata);
        ../../sound/songs/se_w207.o(.rodata);
        ../../sound/songs/se_w207b.o(.rodata);
        ../../sound/songs/se_w215.o(.rodata);
        ../../sound/songs/se_w109.o(.rodata);
        ../../sound/songs/se_w173.o(.rodata);
        ../../sound/songs/se_w280.o(.rodata);
        ../../sound/songs/se_w202.o(.rodata);
        ../../sound/songs/se_w060b.o(.rodata);
        ../../sound/songs/se_w076.o(.rodata);
        ../../sound/songs/se_w080.o(.rodata);
        ../../sound/songs/se_w100.o(.rodata);
        ../../sound/songs/se_w107.o(.rodata);
        ../../sound/songs/se_w166.o(.rodata);
        ../../sound/songs/se_w129.o(.rodata);
        ../../sound/songs/se_w115.o(.rodata);
        ../../sound/songs/se_w112.o(.rodata);
        ../../sound/songs/se_w197.o(.rodata);
        ../../sound/songs/se_w199.o(.rodata);
        ../../sound/songs/se_w236.o(.rodata);
        ../../sound/songs/se_w204.o(.rodata);
        ../../sound/songs/se_w268.o(.rodata);
        ../../sound/songs/se_w070.o(.rodata);
        ../../sound/songs/se_w063.o(.rodata);
        ../../sound/songs/se_w127.o(.rodata);
        ../../sound/songs/se_w179.o(.rodata);
        ../../sound/songs/se_w151.o(.rodata);
        ../../sound/songs/se_w201.o(.rodata);
        ../../sound/songs/se_w161.o(.rodata);
        ../../sound/songs/se_w161b.o(.rodata);
        ../../sound/songs/se_w227.o(.rodata);
        ../../sound/songs/se_w227b.o(.rodata);
        ../../sound/songs/se_w226.o(.rodata);
        ../../sound/songs/se_w208.o(.rodata);
        ../../sound/songs/se_w213.o(.rodata);
        ../../sound/songs/se_w213b.o(.rodata);
        ../../sound/songs/se_w234.o(.rodata);
        ../../sound/songs/se_w260.o(.rodata);
        ../../sound/songs/se_w328.o(.rodata);
        ../../sound/songs/se_w320.o(.rodata);
        ../../sound/songs/se_w255.o(.rodata);
        ../../sound/songs/se_w291.o(.rodata);
        ../../sound/songs/se_w089.o(.rodata);
        ../../sound/songs/se_w239.o(.rodata);
        ../../sound/songs/se_w230.o(.rodata);
        ../../sound/songs/se_w281.o(.rodata);
        ../../sound/songs/se_w327.o(.rodata);
        ../../sound/songs/se_w287.o(.rodata);
        ../../sound/songs/se_w257.o(.rodata);
        ../../sound/songs/se_w253.o(.rodata);
        ../../sound/songs/se_w258.o(.rodata);
        ../../sound/songs/se_w322.o(.rodata);
        ../../sound/songs/se_w298.o(.rodata);
        ../../sound/songs/se_w287b.o(.rodata);
        ../../sound/songs/se_w114.o(.rodata);
        ../../sound/songs/se_w063b.o(.rodata);
        ../../sound/songs/song_248.o(.rodata);
        ../../sound/songs/song_249.o(.rodata);
        ../../sound/songs/song_250.o(.rodata);
        ../../sound/songs/song_251.o(.rodata);
        ../../sound/songs/song_252.o(.rodata);
        ../../sound/songs/song_253.o(.rodata);
        ../../sound/songs/song_254.o(.rodata);
        ../../sound/songs/song_255.o(.rodata);
        ../../sound/songs/song_256.o(.rodata);
        ../../sound/songs/song_257.o(.rodata);
        ../../sound/songs/song_258.o(.rodata);
        ../../sound/songs/song_259.o(.rodata);
        ../../sound/songs/song_260.o(.rodata);
        ../../sound/songs/song_261.o(.rodata);
        ../../sound/songs/song_262.o(.rodata);
        ../../sound/songs/song_263.o(.rodata);
        ../../sound/songs/song_264.o(.rodata);
        ../../sound/songs/song_265.o(.rodata);
        ../../sound/songs/song_266.o(.rodata);
        ../../sound/songs/song_267.o(.rodata);
        ../../sound/songs/song_268.o(.rodata);
        ../../sound/songs/song_269.o(.rodata);
        ../../sound/songs/song_270.o(.rodata);
        ../../sound/songs/song_271.o(.rodata);
        ../../sound/songs/song_272.o(.rodata);
        ../../sound/songs/song_273.o(.rodata);
        ../../sound/songs/song_274.o(.rodata);
        ../../sound/songs/song_275.o(.rodata);
        ../../sound/songs/song_276.o(.rodata);
        ../../sound/songs/song_277.o(.rodata);
        ../../sound/songs/song_278.o(.rodata);
        ../../sound/songs/song_279.o(.rodata);
        ../../sound/songs/song_280.o(.rodata);
        ../../sound/songs/song_281.o(.rodata);
        ../../sound/songs/song_282.o(.rodata);
        ../../sound/songs/song_283.o(.rodata);
        ../../sound/songs/song_284.o(.rodata);
        ../../sound/songs/song_285.o(.rodata);
        ../../sound/songs/song_286.o(.rodata);
        ../../sound/songs/song_287.o(.rodata);
        ../../sound/songs/song_288.o(.rodata);
        ../../sound/songs/song_289.o(.rodata);
        ../../sound/songs/song_290.o(.rodata);
        ../../sound/songs/song_291.o(.rodata);
        ../../sound/songs/song_292.o(.rodata);
        ../../sound/songs/song_293.o(.rodata);
        ../../sound/songs/song_294.o(.rodata);
        ../../sound/songs/song_295.o(.rodata);
        ../../sound/songs/song_296.o(.rodata);
        ../../sound/songs/song_297.o(.rodata);
        ../../sound/songs/song_298.o(.rodata);
        ../../sound/songs/bgm_tetsuji.o(.rodata);
        ../../sound/songs/bgm_field13.o(.rodata);
        ../../sound/songs/bgm_kachi22.o(.rodata);
        ../../sound/songs/bgm_kachi2.o(.rodata);
        ../../sound/songs/bgm_kachi3.o(.rodata);
        ../../sound/songs/bgm_kachi5.o(.rodata);
        ../../sound/songs/bgm_pcc.o(.rodata);
        ../../sound/songs/bgm_nibi.o(.rodata);
        ../../sound/songs/bgm_suikun.o(.rodata);
        ../../sound/songs/bgm_dooro1.o(.rodata);
        ../../sound/songs/bgm_dooro_x1.o(.rodata);
        ../../sound/songs/bgm_dooro_x3.o(.rodata);
        ../../sound/songs/bgm_machi_s2.o(.rodata);
        ../../sound/songs/bgm_machi_s4.o(.rodata);
        ../../sound/songs/bgm_gim.o(.rodata);
        ../../sound/songs/bgm_naminori.o(.rodata);
        ../../sound/songs/bgm_dan01.o(.rodata);
        ../../sound/songs/bgm_fanfa1.o(.rodata);
        ../../sound/songs/bgm_me_asa.o(.rodata);
        ../../sound/songs/bgm_me_bachi.o(.rodata);
        ../../sound/songs/bgm_fanfa4.o(.rodata);
        ../../sound/songs/bgm_fanfa5.o(.rodata);
        ../../sound/songs/bgm_me_waza.o(.rodata);
        ../../sound/songs/bgm_bijyutu.o(.rodata);
        ../../sound/songs/bgm_dooro_x4.o(.rodata);
        ../../sound/songs/bgm_fune_kan.o(.rodata);
        ../../sound/songs/bgm_me_shinka.o(.rodata);
        ../../sound/songs/bgm_shinka.o(.rodata);
        ../../sound/songs/bgm_me_wasure.o(.rodata);
        ../../sound/songs/bgm_syoujoeye.o(.rodata);
        ../../sound/songs/bgm_boyeye.o(.rodata);
        ../../sound/songs/bgm_dan02.o(.rodata);
        ../../sound/songs/bgm_machi_s3.o(.rodata);
        ../../sound/songs/bgm_odamaki.o(.rodata);
        ../../sound/songs/bgm_b_tower.o(.rodata);
        ../../sound/songs/bgm_swimeye.o(.rodata);
        ../../sound/songs/bgm_dan03.o(.rodata);
        ../../sound/songs/bgm_me_kinomi.o(.rodata);
        ../../sound/songs/bgm_me_tama.o(.rodata);
        ../../sound/songs/bgm_me_b_big.o(.rodata);
        ../../sound/songs/bgm_me_b_small.o(.rodata);
        ../../sound/songs/bgm_me_zannen.o(.rodata);
        ../../sound/songs/bgm_bd_time.o(.rodata);
        ../../sound/songs/bgm_test1.o(.rodata);
        ../../sound/songs/bgm_test2.o(.rodata);
        ../../sound/songs/bgm_test3.o(.rodata);
        ../../sound/songs/bgm_test4.o(.rodata);
        ../../sound/songs/bgm_test.o(.rodata);
        ../../sound/songs/bgm_gomachi0.o(.rodata);
        ../../sound/songs/bgm_gotown.o(.rodata);
        ../../sound/songs/bgm_pokecen.o(.rodata);
        ../../sound/songs/bgm_nextroad.o(.rodata);
        ../../sound/songs/bgm_granroad.o(.rodata);
        ../../sound/songs/bgm_cycling.o(.rodata);
        ../../sound/songs/bgm_friendly.o(.rodata);
        ../../sound/songs/bgm_mishiro.o(.rodata);
        ../../sound/songs/bgm_tozan.o(.rodata);
        ../../sound/songs/bgm_girleye.o(.rodata);
        ../../sound/songs/bgm_minamo.o(.rodata);
        ../../sound/songs/bgm_ashroad.o(.rodata);
        ../../sound/songs/bgm_event0.o(.rodata);
        ../../sound/songs/bgm_deepdeep.o(.rodata);
        ../../sound/songs/bgm_kachi1.o(.rodata);
        ../../sound/songs/bgm_title3.o(.rodata);
        ../../sound/songs/bgm_demo1.o(.rodata);
        ../../sound/songs/bgm_girl_sup.o(.rodata);
        ../../sound/songs/bgm_hageshii.o(.rodata);
        ../../sound/songs/bgm_kakkoii.o(.rodata);
        ../../sound/songs/bgm_kazanbai.o(.rodata);
        ../../sound/songs/bgm_aqa_0.o(.rodata);
        ../../sound/songs/bgm_tsuretek.o(.rodata);
        ../../sound/songs/bgm_boy_sup.o(.rodata);
        ../../sound/songs/bgm_rainbow.o(.rodata);
        ../../sound/songs/bgm_ayasii.o(.rodata);
        ../../sound/songs/bgm_kachi4.o(.rodata);
        ../../sound/songs/bgm_ropeway.o(.rodata);
        ../../sound/songs/bgm_casino.o(.rodata);
        ../../sound/songs/bgm_hightown.o(.rodata);
        ../../sound/songs/bgm_safari.o(.rodata);
        ../../sound/songs/bgm_c_road.o(.rodata);
        ../../sound/songs/bgm_ajito.o(.rodata);
        ../../sound/songs/bgm_m_boat.o(.rodata);
        ../../sound/songs/bgm_m_dungon.o(.rodata);
        ../../sound/songs/bgm_finecity.o(.rodata);
        ../../sound/songs/bgm_machupi.o(.rodata);
        ../../sound/songs/bgm_p_school.o(.rodata);
        ../../sound/songs/bgm_dendou.o(.rodata);
        ../../sound/songs/bgm_tonekusa.o(.rodata);
        ../../sound/songs/bgm_maborosi.o(.rodata);
        ../../sound/songs/bgm_con_fan.o(.rodata);
        ../../sound/songs/bgm_contest0.o(.rodata);
        ../../sound/songs/bgm_mgm0.o(.rodata);
        ../../sound/songs/bgm_t_battle.o(.rodata);
        ../../sound/songs/bgm_ooame.o(.rodata);
        ../../sound/songs/bgm_hideri.o(.rodata);
        ../../sound/songs/bgm_runecity.o(.rodata);
        ../../sound/songs/bgm_con_k.o(.rodata);
        ../../sound/songs/bgm_eikou_r.o(.rodata);
        ../../sound/songs/bgm_karakuri.o(.rodata);
        ../../sound/songs/bgm_hutago.o(.rodata);
        ../../sound/songs/bgm_sitennou.o(.rodata);
        ../../sound/songs/bgm_yama_eye.o(.rodata);
        ../../sound/songs/bgm_conlobby.o(.rodata);
        ../../sound/songs/bgm_inter_v.o(.rodata);
        ../../sound/songs/bgm_daigo.o(.rodata);
        ../../sound/songs/bgm_thankfor.o(.rodata);
        ../../sound/songs/bgm_end.o(.rodata);
        ../../sound/songs/bgm_battle27.o(.rodata);
        ../../sound/songs/bgm_battle31.o(.rodata);
        ../../sound/songs/bgm_battle20.o(.rodata);
        ../../sound/songs/bgm_battle32.o(.rodata);
        ../../sound/songs/bgm_battle33.o(.rodata);
        ../../sound/songs/bgm_battle36.o(.rodata);
        ../../sound/songs/bgm_battle34.o(.rodata);
        ../../sound/songs/bgm_battle35.o(.rodata);
        ../../sound/songs/bgm_battle38.o(.rodata);
        ../../sound/songs/bgm_battle30.o(.rodata);
        ../../sound/songs/bgm_radio_tower_occupied.o(.rodata);
    } =0

    lib_rodata :
    ALIGN(4)
    {
        src/libs/agb_flash.o(.rodata);
        src/libs/agb_flash_1m.o(.rodata);
        src/libs/agb_flash_mx.o(.rodata);
        src/libs/agb_flash_le.o(.rodata);
        src/libs/siirtc.o(.rodata);
        ../../tools/agbcc/lib/libgcc.a:_udivdi3.o(.rodata);
    } =0

    . = 0x8D00000;

    gfx_data :
    ALIGN(4)
    {
        data/graphics.o(gfx_data);
    } =0

    /* DWARF 2 sections */
    .debug_aranges  0 : { *(.debug_aranges) }
    .debug_pubnames 0 : { *(.debug_pubnames) }
    .debug_info     0 : { *(.debug_info) }
    .debug_abbrev   0 : { *(.debug_abbrev) }
    .debug_line     0 : { *(.debug_line) }
    .debug_frame    0 : { *(.debug_frame) }
    .debug_str      0 : { *(.debug_str) }
    .debug_loc      0 : { *(.debug_loc) }
    .debug_macinfo  0 : { *(.debug_macinfo) }

    . = 0x8F00000;

    korean_data :
    ALIGN(4)
    {
        data/korean.o(korean_data);
        src/engine/korean.o(.text);
    } =0

    /* Discard everything not specifically mentioned above. */
    /DISCARD/ :
    {
        *(*);
    }
}
